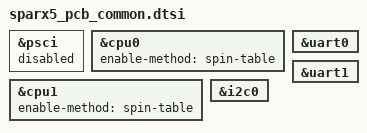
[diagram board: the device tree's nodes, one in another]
/dts-v1/;
#include "sparx5.dtsi"
&psci {
	status = "disabled";
};
&cpu0 {
	enable-method = "spin-table";
};
&cpu1 {
	enable-method = "spin-table";
};
&uart0 {
	status = "okay";
};
&uart1 {
	status = "okay";
};
&i2c0 {
	status = "okay";
};
